# EOS-S3 register map
File version: 0.1
CPU: CM4 r0p1, selectable endian, MPU, FPU, 3 interrupt priority bits
Registers are 32-bit, read-write, reset 0x0 unless marked. A register's access mark holds for its fields unless they carry their own. Offsets are from the block's base; [hi:lo] are bit positions; {n}, {i} and the like mark numbered series.

## IOMUX — IO Multiplexing Control
Base 0x40004C00
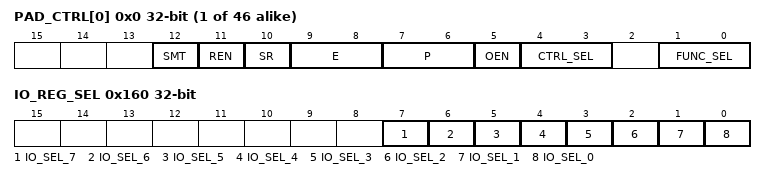
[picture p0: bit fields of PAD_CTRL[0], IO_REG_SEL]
{0x0+4i} PAD_CTRL[{i}] (i=0..45) — PAD_[{i}] control register
  [12] SMT — Schmitt Trigger
    0=disable_trigger (Disable the Schmitt trigger); 1=enable_trigger (Enable the Schmitt trigger)
  [11] REN — Receive Enable
    0=disable_receive; 1=enable_receive
  [10] SR — Slew Rate
    0=slow (half frequency) slew rate; 1=fast slew rate
  [9:8] E — Driver Strength
    0=current_2ma (Configures the drive current at 2mA); 1=current_4ma (Configures the drive current at 4mA); 2=current_8ma (Configures the drive current at 8mA); 3=current_12ma (Configures the drive current at 12mA)
  [7:6] P — Driver state control
    0=z (floating, high impedance); 1=pull-up mode; 2=pull-down mode; 3=keeper (bus keeper mode)
  [5] OEN — Active low output enable
    0=normal_operation; 1=driver_disabled
  [4:3] CTRL_SEL — Control selection for IO Output. 0x0 = A0 registers, 0x1 = Others, 0x2 = Fabric
    0=a0_registers; 1=others; 2=fabric
  [1:0] FUNC_SEL — Functional selection for IO output. Refer to IO Mux
    {v}=alternative_{v} (Select alternative function {v}) (v=0..3)
0x100 SDA0_SEL_REG — Select pad for SDA function in I2C0 (only pad 1 is selectable)
  [0] SEL
    0=default_undefined (Documentation lacking, guessed meaning: Selects pad #1 for the SDA function in I2C0); 1=pad_01 (Selects pad #1 for the SDA function in I2C0)
0x104 SDA1_SEL_REG — Select pad for SDA function in I2C1 (3 pads available)
  [1:0] SEL
    0=default_undefined (Documentation lacking, guessed meaning: Select pad #15 for the SDA function in I2C1); 1=pad_15 (Select pad #15 for the SDA function in I2C1); 2=pad_32 (Select pad #32 for the SDA function in I2C1); 3=pad_44 (Select pad #44 for the SDA function in I2C1)
0x108 SDA2_SEL_REG — Select pad for SDA function in I2C2 (only pad 41 is selectable)
  [0] SEL
    0=default_undefined (Documentation lacking, guessed meaning: Selects pad #41 for the SDA function in I2C2); 1=pad_41 (Selects pad #41 for the SDA function in I2C2)
0x10C SCL0_SEL_REG — Select pad for SCL function in I2C0 (only pad 0 is selectable)
  [0] SEL
    0=default_undefined (Documentation lacking, guessed meaning: Selects pad #0 for the SCL function in I2C0); 1=pad_00 (Selects pad #0 for the SCL function in I2C0)
0x110 SCL1_SEL_REG — Select pad for SCL function in I2C1 (3 pads available)
  [1:0] SEL
    0=default_undefined (Documentation lacking, guessed meaning: Select pad #14 for the SCL function in I2C1); 1=pad_14 (Select pad #14 for the SCL function in I2C1); 2=pad_33 (Select pad #33 for the SCL function in I2C1); 3=pad_45 (Select pad #45 for the SCL function in I2C1)
0x114 SCL2_SEL_REG — Select pad for SCL function in I2C2 (only pad 40 is selectable)
  [0] SEL
    0=default_undefined (Documentation lacking, guessed meaning: Selects pad #40 for the SCL function in I2C2); 1=pad_40 (Selects pad #40 for the SCL function in I2C2)
0x118 SPIs_CLK_SEL — Select pad for SPI CLK function (only pad 16 is selectable)
  [0] SEL
0x11C SPIs_SSn_SEL — Select pad for SPI SS function (only pad 20 is selectable)
  [0] SEL
0x120 SPIs_MOSI_SEL — Select pad for SPI MOSI function (only pad 19 is selectable)
  [0] SEL
0x124 SPIs_MISO_SEL — Select pad for SPI MISO function (only pad 36 is selectable)
  [0] SEL
0x128 PDM_DATA_SELE — Select pad for PDM microphone data line
  [1:0] SEL
    0=undefined (0:0 in documentation); 1=pad_10 (Selects pad #10 for PDM data line); 2=pad_28 (Selects pad #28 for PDM data line)
0x12C I2S_DATA_SELECT — Select pad for the I2S Serial Data (SD)
  [1:0] SEL
    0=undefined (0:0 in documentation); 1=pad_10 (Selects pad #10 for I2S data line); 2=pad_28 (Selects pad #28 for I2S data line)
0x134 UART_rxd_SEL — a
  [2:0] SEL
    0=undefined (0:0 in documentation); 1=pad_14 (Selects pad #14 for UART RXD line); 2=pad_16 (Selects pad #16 for UART RXD line); 3=pad_25 (Selects pad #25 for UART RXD line); 4=pad_45 (Selects pad #45 for UART RXD line)
0x138 IrDA_Sirin_SEL — Select pad for SIREN in function
  [2:0] SEL
    0=undefined (0:0 in documentation); 1=pad_06 (Selects pad #14 for Siren in line); 2=pad_15 (Selects pad #15 for Siren in line); 3=pad_21 (Selects pad #21 for Siren in line); 4=pad_24 (Selects pad #24 for Siren in line); 5=pad_28 (Selects pad #28 for Siren in line); 6=pad_40 (Selects pad #40 for Siren in line); 7=pad_44 (Selects pad #44 for Siren in line)
0x13C S_INTR_0_SEL_REG — Select pad that triggers GPIO interrupt 0
  [0] SEL
    0=undefined (0:0 in documentation); 1=pad_03 (Selects pad #3 as the trigger)
0x140 S_INTR_1_SEL_REG — Select pad that triggers GPIO interrupt 1
  [2:0] SEL
    0=undefined (0:0 in documentation); 1=pad_02 (Selects pad #2 as the trigger); 2=pad_06 (Selects pad #6 as the trigger); 3=pad_18 (Selects pad #18 as the trigger); 4=pad_24 (Selects pad #24 as the trigger); 5=pad_35 (Selects pad #35 as the trigger); 6=pad_36 (Selects pad #36 as the trigger)
0x144 S_INTR_2_SEL — Select pad that triggers GPIO interrupt 2
  [2:0] SEL
    0=undefined (0:0 in documentation); 1=pad_04 (Selects pad #4 as the trigger); 2=pad_08 (Selects pad #8 as the trigger); 3=pad_21 (Selects pad #21 as the trigger); 4=pad_25 (Selects pad #25 as the trigger); 5=pad_37 (Selects pad #37 as the trigger); 6=pad_38 (Selects pad #38 as the trigger)
0x148 S_INTR_3_SEL — Select pad that triggers GPIO interrupt 3
  [2:0] SEL
    0=undefined (0:0 in documentation); 1=pad_05 (Selects pad #2 as the trigger); 2=pad_09 (Selects pad #9 as the trigger); 3=pad_22 (Selects pad #22 as the trigger); 4=pad_28 (Selects pad #28 as the trigger); 5=pad_39 (Selects pad #39 as the trigger); 6=pad_40 (Selects pad #40 as the trigger)
0x14C S_INTR_4_SEL — Select pad that triggers GPIO interrupt 4
  [2:0] SEL
    0=undefined (0:0 in documentation); 1=pad_07 (Selects pad #7 as the trigger); 2=pad_10 (Selects pad #10 as the trigger); 3=pad_26 (Selects pad #26 as the trigger); 4=pad_29 (Selects pad #29 as the trigger); 5=pad_44 (Selects pad #44 as the trigger)
0x150 S_INTR_5_SEL — Select pad that triggers GPIO interrupt 5
  [2:0] SEL
    0=undefined (0:0 in documentation); 1=pad_11 (Selects pad #11 as the trigger); 2=pad_14 (Selects pad #14 as the trigger); 3=pad_27 (Selects pad #27 as the trigger); 4=pad_30 (Selects pad #30 as the trigger); 5=pad_45 (Selects pad #45 as the trigger)
0x154 S_INTR_6_SEL — Select pad that triggers GPIO interrupt 6
  [2:0] SEL
    0=undefined (0:0 in documentation); 1=pad_12 (Selects pad #12 as the trigger); 2=pad_15 (Selects pad #15 as the trigger); 3=pad_31 (Selects pad #31 as the trigger); 4=pad_32 (Selects pad #32 as the trigger); 5=pad_41 (Selects pad #41 as the trigger)
0x158 S_INTR_7_SEL — Select pad that triggers GPIO interrupt 7
  [2:0] SEL
    0=undefined (0:0 in documentation); 1=pad_13 (Selects pad #13 as the trigger); 2=pad_23 (Selects pad #23 as the trigger); 3=pad_33 (Selects pad #33 as the trigger); 4=pad_34 (Selects pad #34 as the trigger); 5=pad_42 (Selects pad #42 as the trigger)
0x15C NUARTCTS_SEL — Pad Selection for the CTS nUART function
  [1:0] SEL
0x160 IO_REG_SEL — Selects which IO input will be registered (Pads used as GPIOS)
  [7] IO_SEL_7 — Select pad for IO maped to bit 7
    0=pad_23 (Enable pad #23 as GPIO); 1=pad_45 (Enable pad #45 as GPIO)
  [6] IO_SEL_6 — Select pad for IO maped to bit 6
    0=pad_22 (Enable pad #22 as GPIO); 1=pad_38 (Enable pad #38 as GPIO)
  [5] IO_SEL_5 — Select pad for IO maped to bit 5
    0=pad_21 (Enable pad #21 as GPIO); 1=pad_26 (Enable pad #26 as GPIO)
  [4] IO_SEL_4 — Select pad for IO maped to bit 4
    0=pad_18 (Enable pad #18 as GPIO); 1=pad_31 (Enable pad #31 as GPIO)
  [3] IO_SEL_3 — Select pad for IO maped to bit 3
    0=pad_14 (Enable pad #14 as GPIO); 1=pad_30 (Enable pad #30 as GPIO)
  [2] IO_SEL_2 — Select pad for IO maped to bit 2
    0=pad_11 (Enable pad #11 as GPIO); 1=pad_28 (Enable pad #28 as GPIO)
  [1] IO_SEL_1 — Select pad for IO maped to bit 1
    0=pad_09 (Enable pad #9 as GPIO); 1=pad_26 (Enable pad #26 as GPIO)
  [0] IO_SEL_0 — Select pad for IO maped to bit 0
    0=pad_06 (Enable pad #6 as GPIO); 1=pad_24 (Enable pad #24 as GPIO)
0x170 SW_CLK_SEL — Selection for SWD clock pad (SCK)
  [0] SEL
    0=select_strap_pad_14_45 (pad #14/#45 (pad selection will depend on pad #8, See ch. 30 of TechRef Manual)); 1=undefined (Lacking documentation. Might mean the same as `select_strap_pad`)
0x174 SW_IO_SEL — Selection for SWD IO pad (SDIO)
  [0] SEL
    0=select_strap_pad_15_44 (pad #15/#44 (pad selection will depend on pad #8, See ch. 30 of TechRef Manual)); 1=undefined (Lacking documentation. Might mean the same as `select_strap_pad`)
0x180 FBIO_SEL_1 — Lacking proper documentation. Configuration of pins 0-31 related to Fabric
  [31:0] SEL
    0=undefined (Lacking documentation. Guess: Leaves pad unselected); 1=select_pad (Lacking documentation. Guess: Activates some sort of FPGA Fabric control for pads 0-31)
0x184 FBIO_SEL_2 — Lacking proper documentation. Configuration of pins 32-45 related to Fabric
  [13:0] SEL
    0=undefined (Lacking documentation. Guess: Leaves pad unselected); 1=select_pad (Lacking documentation. Guess: Activates some sort of FPGA Fabric control for pads 32-45)
0x190 SPI_SENSOR_MISO_SEL — Selects pad for MISO function for the sensor SPI
  [1:0] SEL
    0=undefined (0:0 in documentation); 1=pad_08 (Selects pad #8 for sensor SPI MISO); 2=pad_29 (Selects pad #29 for sensor SPI MISO)
0x194 SPI_SENSOR_MOSI_SEL — Selects pad for MOSI function for the sensor SPI
  [1:0] SEL
    0=undefined (0:0 in documentation); 1=pad_06 (Selects pad #6 for sensor SPI MISO); 2=pad_28 (Selects pad #28 for sensor SPI MISO)
0x1A0 I2S_WD_CLKIN_SEL — Selects pad for the I2S Data-Word Select (WS)
  [0] SEL
0x1A4 I2S_CLKIN_SEL — Selects pad for I2S clock (SCK)
  [0] SEL
0x1A8 PDM_STAT_IN_SEL — Selects pin for PDM STATUS_IN function
  [1:0] SEL
0x1AC PDM_CLKIN_SEL — Selects pin for PDM CLKIN source (AP PDM CKO IN)
  [0] SEL
